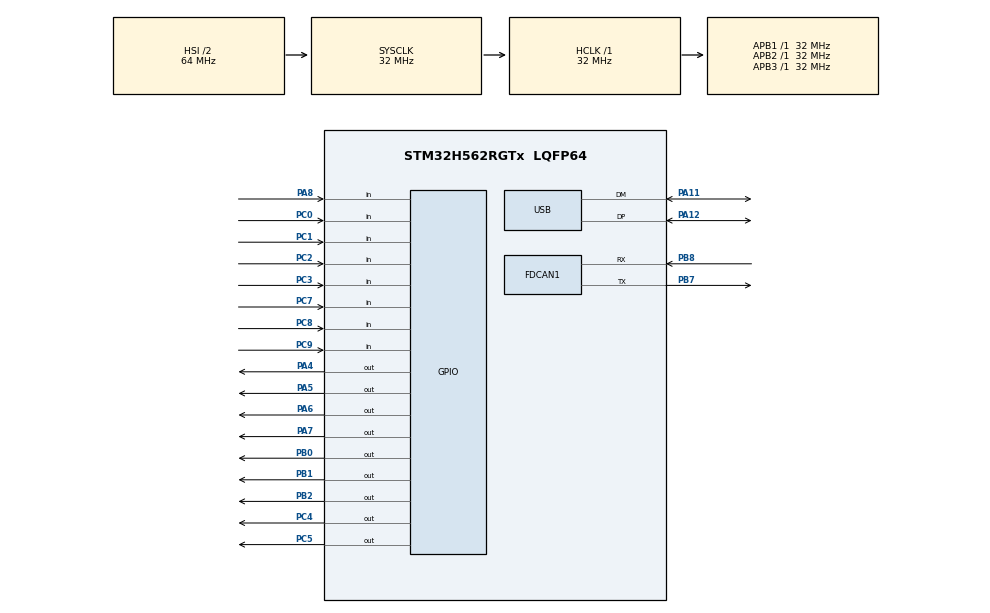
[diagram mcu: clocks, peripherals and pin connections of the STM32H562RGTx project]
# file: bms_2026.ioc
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BOOTPATH.BootPathName=LEGACY
BOOTPATH.UserSelectedBootPath=LEGACY
CORTEX_M33_NS.userName=CORTEX_M33
FDCAN1.CalculateBaudRateNominal=1791666
FDCAN1.CalculateTimeBitNominal=558
FDCAN1.CalculateTimeQuantumNominal=186.04651162790697
Mcu.Family=STM32H5
Mcu.Name=STM32H562RGTx
Mcu.Package=LQFP64
NVIC.PriorityGroup=NVIC_PRIORITYGROUP_4
PA11.Mode=Device
PA11.Signal=USB_DM
PA12.Mode=Device
PA12.Signal=USB_DP
PA4.Signal=GPIO_Output
PA5.Signal=GPIO_Output
PA6.Signal=GPIO_Output
PA7.Signal=GPIO_Output
PA8.Signal=GPIO_Input
PB0.Signal=GPIO_Output
PB1.Signal=GPIO_Output
PB2.Signal=GPIO_Output
PB7.Mode=FDCAN_Activate
PB7.Signal=FDCAN1_TX
PB8.Mode=FDCAN_Activate
PB8.Signal=FDCAN1_RX
PC0.Signal=GPIO_Input
PC1.Signal=GPIO_Input
PC2.Signal=GPIO_Input
PC3.Signal=GPIO_Input
PC4.Signal=GPIO_Output
PC5.Signal=GPIO_Output
PC7.Signal=GPIO_Input
PC8.Signal=GPIO_Input
PC9.Signal=GPIO_Input
ProjectManager.HeapSize=0x200
ProjectManager.StackSize=0x400
ProjectManager.TargetToolchain=STM32CubeIDE
RCC.ADCFreq_Value=32000000
RCC.AHBFreq_Value=32000000
RCC.APB1Freq_Value=32000000
RCC.APB1TimFreq_Value=32000000
RCC.APB2Freq_Value=32000000
RCC.APB2TimFreq_Value=32000000
RCC.APB3Freq_Value=32000000
RCC.CSI_VALUE=4000000
RCC.CortexFreq_Value=32000000
RCC.EPOD_VALUE=4000000
RCC.FDCANClockSelection=RCC_FDCANCLKSOURCE_PLL1Q
RCC.HCLKFreq_Value=32000000
RCC.HSE_VALUE=25000000
RCC.HSI48_VALUE=48000000
RCC.HSI_VALUE=64000000
RCC.LSE_VALUE=32768
RCC.LSIRC_VALUE=32000
RCC.PLL1Q=6
RCC.SYSCLKFreq_VALUE=32000000
RCC.USBFreq_Value=48000000
RCC.VCOOutputFreq_Value=516000000
USB.VirtualMode=Device_Only
VP_BOOTPATH_VS_BOOTPATH.Mode=BP_Activate
VP_CORTEX_M33_NS_VS_Hclk.Mode=Hclk_Mode
VP_MEMORYMAP_VS_MEMORYMAP.Mode=CurAppReg
VP_PWR_VS_LPOM.Mode=PowerOptimisation
VP_PWR_VS_SECSignals.Mode=Security/Privilege
board=custom

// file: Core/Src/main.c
/* USER CODE BEGIN Header */
/**
  ******************************************************************************
  * @file           : main.c
  * @brief          : Main program body
  ******************************************************************************
  * @attention
  *
  * Copyright (c) 2026 STMicroelectronics.
  * All rights reserved.
  *
  * This software is licensed under terms that can be found in the LICENSE file
  * in the root directory of this software component.
  * If no LICENSE file comes with this software, it is provided AS-IS.
  *
  ******************************************************************************
  */
/* USER CODE END Header */
#include "main.h"

/* USER CODE BEGIN PD */
#define NUM_RELAYS 8
#define DEBOUNCE_MS 50
/* USER CODE END PD */

FDCAN_HandleTypeDef hfdcan1;

PCD_HandleTypeDef hpcd_USB_DRD_FS;

// Button-to-relay pin mapping
GPIO_TypeDef* btn_port[NUM_RELAYS] = {GPIOC, GPIOC, GPIOC, GPIOC, GPIOC, GPIOC, GPIOC, GPIOA};
uint16_t btn_pin[NUM_RELAYS] = {GPIO_PIN_0, GPIO_PIN_1, GPIO_PIN_2, GPIO_PIN_3, GPIO_PIN_7, GPIO_PIN_8, GPIO_PIN_9, GPIO_PIN_8};

GPIO_TypeDef* relay_port[NUM_RELAYS] = {GPIOA, GPIOA, GPIOA, GPIOA, GPIOC, GPIOC, GPIOB, GPIOB};
uint16_t relay_pin[NUM_RELAYS] = {GPIO_PIN_4, GPIO_PIN_5, GPIO_PIN_6, GPIO_PIN_7, GPIO_PIN_4, GPIO_PIN_5, GPIO_PIN_0, GPIO_PIN_1};

uint8_t relay_state[NUM_RELAYS] = {0};
uint8_t btn_stable[NUM_RELAYS] = {1, 1, 1, 1, 1, 1, 1, 1};
uint8_t btn_raw[NUM_RELAYS] = {1, 1, 1, 1, 1, 1, 1, 1};
uint32_t btn_debounce_time[NUM_RELAYS] = {0};

void SystemClock_Config(void);
static void MX_GPIO_Init(void);
static void MX_FDCAN1_Init(void);
static void MX_USB_PCD_Init(void);

int main(void)
{

  /* MCU Configuration--------------------------------------------------------*/

  /* Reset of all peripherals, Initializes the Flash interface and the Systick. */
  HAL_Init();

  /* Configure the system clock */
  SystemClock_Config();

  /* Initialize all configured peripherals */
  MX_GPIO_Init();
  MX_FDCAN1_Init();
  MX_USB_PCD_Init();

  /* Infinite loop */
  while (1)
  {
	  /* USER CODE BEGIN 3 */
	  for (int i = 0; i < NUM_RELAYS; i++) {
	      uint8_t reading = HAL_GPIO_ReadPin(btn_port[i], btn_pin[i]);

	      if (reading != btn_raw[i]) {
	          btn_debounce_time[i] = HAL_GetTick();
	          btn_raw[i] = reading;
	      }

	      if ((HAL_GetTick() - btn_debounce_time[i]) > DEBOUNCE_MS) {
	          if (btn_raw[i] != btn_stable[i]) {
	              btn_stable[i] = btn_raw[i];
	              // Toggle on press (falling edge)
	              if (btn_stable[i] == GPIO_PIN_RESET) {
	                  relay_state[i] ^= 1;
	                  HAL_GPIO_WritePin(relay_port[i], relay_pin[i],
	                      relay_state[i] ? GPIO_PIN_SET : GPIO_PIN_RESET);
	              }
	          }
	      }
	  }
	  /* USER CODE END 3 */
  }
}

void SystemClock_Config(void)
{
  RCC_OscInitTypeDef RCC_OscInitStruct = {0};
  RCC_ClkInitTypeDef RCC_ClkInitStruct = {0};

  /** Configure the main internal regulator output voltage
  */
  __HAL_PWR_VOLTAGESCALING_CONFIG(PWR_REGULATOR_VOLTAGE_SCALE3);

  while(!__HAL_PWR_GET_FLAG(PWR_FLAG_VOSRDY)) {}

  /** Initializes the RCC Oscillators according to the specified parameters
  * in the RCC_OscInitTypeDef structure.
  */
  RCC_OscInitStruct.OscillatorType = RCC_OSCILLATORTYPE_HSI48|RCC_OSCILLATORTYPE_HSI
                              |RCC_OSCILLATORTYPE_CSI;
  RCC_OscInitStruct.HSIState = RCC_HSI_ON;
  RCC_OscInitStruct.HSIDiv = RCC_HSI_DIV2;
  RCC_OscInitStruct.HSICalibrationValue = RCC_HSICALIBRATION_DEFAULT;
  RCC_OscInitStruct.HSI48State = RCC_HSI48_ON;
  RCC_OscInitStruct.CSIState = RCC_CSI_ON;
  RCC_OscInitStruct.CSICalibrationValue = RCC_CSICALIBRATION_DEFAULT;
  RCC_OscInitStruct.PLL.PLLState = RCC_PLL_ON;
  RCC_OscInitStruct.PLL.PLLSource = RCC_PLL1_SOURCE_CSI;
  RCC_OscInitStruct.PLL.PLLM = 1;
  RCC_OscInitStruct.PLL.PLLN = 129;
  RCC_OscInitStruct.PLL.PLLP = 2;
  RCC_OscInitStruct.PLL.PLLQ = 6;
  RCC_OscInitStruct.PLL.PLLR = 2;
  RCC_OscInitStruct.PLL.PLLRGE = RCC_PLL1_VCIRANGE_2;
  RCC_OscInitStruct.PLL.PLLVCOSEL = RCC_PLL1_VCORANGE_WIDE;
  RCC_OscInitStruct.PLL.PLLFRACN = 0;
  if (HAL_RCC_OscConfig(&RCC_OscInitStruct) != HAL_OK)
  {
    Error_Handler();
  }

  /** Initializes the CPU, AHB and APB buses clocks
  */
  RCC_ClkInitStruct.ClockType = RCC_CLOCKTYPE_HCLK|RCC_CLOCKTYPE_SYSCLK
                              |RCC_CLOCKTYPE_PCLK1|RCC_CLOCKTYPE_PCLK2
                              |RCC_CLOCKTYPE_PCLK3;
  RCC_ClkInitStruct.SYSCLKSource = RCC_SYSCLKSOURCE_HSI;
  RCC_ClkInitStruct.AHBCLKDivider = RCC_SYSCLK_DIV1;
  RCC_ClkInitStruct.APB1CLKDivider = RCC_HCLK_DIV1;
  RCC_ClkInitStruct.APB2CLKDivider = RCC_HCLK_DIV1;
  RCC_ClkInitStruct.APB3CLKDivider = RCC_HCLK_DIV1;

  if (HAL_RCC_ClockConfig(&RCC_ClkInitStruct, FLASH_LATENCY_1) != HAL_OK)
  {
    Error_Handler();
  }

  /** Configure the programming delay
  */
  __HAL_FLASH_SET_PROGRAM_DELAY(FLASH_PROGRAMMING_DELAY_0);
}

static void MX_FDCAN1_Init(void)
{

  hfdcan1.Instance = FDCAN1;
  hfdcan1.Init.ClockDivider = FDCAN_CLOCK_DIV1;
  hfdcan1.Init.FrameFormat = FDCAN_FRAME_CLASSIC;
  hfdcan1.Init.Mode = FDCAN_MODE_NORMAL;
  hfdcan1.Init.AutoRetransmission = DISABLE;
  hfdcan1.Init.TransmitPause = DISABLE;
  hfdcan1.Init.ProtocolException = DISABLE;
  hfdcan1.Init.NominalPrescaler = 16;
  hfdcan1.Init.NominalSyncJumpWidth = 1;
  hfdcan1.Init.NominalTimeSeg1 = 1;
  hfdcan1.Init.NominalTimeSeg2 = 1;
  hfdcan1.Init.DataPrescaler = 1;
  hfdcan1.Init.DataSyncJumpWidth = 1;
  hfdcan1.Init.DataTimeSeg1 = 1;
  hfdcan1.Init.DataTimeSeg2 = 1;
  hfdcan1.Init.StdFiltersNbr = 0;
  hfdcan1.Init.ExtFiltersNbr = 0;
  hfdcan1.Init.TxFifoQueueMode = FDCAN_TX_FIFO_OPERATION;
  if (HAL_FDCAN_Init(&hfdcan1) != HAL_OK)
  {
    Error_Handler();
  }

}

static void MX_USB_PCD_Init(void)
{

  hpcd_USB_DRD_FS.Instance = USB_DRD_FS;
  hpcd_USB_DRD_FS.Init.dev_endpoints = 8;
  hpcd_USB_DRD_FS.Init.speed = USBD_FS_SPEED;
  hpcd_USB_DRD_FS.Init.phy_itface = PCD_PHY_EMBEDDED;
  hpcd_USB_DRD_FS.Init.Sof_enable = DISABLE;
  hpcd_USB_DRD_FS.Init.low_power_enable = DISABLE;
  hpcd_USB_DRD_FS.Init.lpm_enable = DISABLE;
  hpcd_USB_DRD_FS.Init.battery_charging_enable = DISABLE;
  hpcd_USB_DRD_FS.Init.vbus_sensing_enable = DISABLE;
  hpcd_USB_DRD_FS.Init.bulk_doublebuffer_enable = DISABLE;
  hpcd_USB_DRD_FS.Init.iso_singlebuffer_enable = DISABLE;
  if (HAL_PCD_Init(&hpcd_USB_DRD_FS) != HAL_OK)
  {
    Error_Handler();
  }

}

static void MX_GPIO_Init(void)
{
  GPIO_InitTypeDef GPIO_InitStruct = {0};

  /* GPIO Ports Clock Enable */
  __HAL_RCC_GPIOC_CLK_ENABLE();
  __HAL_RCC_GPIOA_CLK_ENABLE();
  __HAL_RCC_GPIOB_CLK_ENABLE();

  /*Configure GPIO pin Output Level */
  HAL_GPIO_WritePin(GPIOA, GPIO_PIN_4|GPIO_PIN_5|GPIO_PIN_6|GPIO_PIN_7, GPIO_PIN_RESET);

  /*Configure GPIO pin Output Level */
  HAL_GPIO_WritePin(GPIOC, GPIO_PIN_4|GPIO_PIN_5, GPIO_PIN_RESET);

  /*Configure GPIO pin Output Level */
  HAL_GPIO_WritePin(GPIOB, GPIO_PIN_0|GPIO_PIN_1|GPIO_PIN_2, GPIO_PIN_RESET);

  /*Configure GPIO pins : PC0 PC1 PC2 PC3
                           PC7 PC8 PC9 */
  GPIO_InitStruct.Pin = GPIO_PIN_0|GPIO_PIN_1|GPIO_PIN_2|GPIO_PIN_3
                          |GPIO_PIN_7|GPIO_PIN_8|GPIO_PIN_9;
  GPIO_InitStruct.Mode = GPIO_MODE_INPUT;
  GPIO_InitStruct.Pull = GPIO_PULLUP;
  HAL_GPIO_Init(GPIOC, &GPIO_InitStruct);

  /*Configure GPIO pins : PA4 PA5 PA6 PA7 */
  GPIO_InitStruct.Pin = GPIO_PIN_4|GPIO_PIN_5|GPIO_PIN_6|GPIO_PIN_7;
  GPIO_InitStruct.Mode = GPIO_MODE_OUTPUT_PP;
  GPIO_InitStruct.Pull = GPIO_NOPULL;
  GPIO_InitStruct.Speed = GPIO_SPEED_FREQ_LOW;
  HAL_GPIO_Init(GPIOA, &GPIO_InitStruct);

  /*Configure GPIO pins : PC4 PC5 */
  GPIO_InitStruct.Pin = GPIO_PIN_4|GPIO_PIN_5;
  GPIO_InitStruct.Mode = GPIO_MODE_OUTPUT_PP;
  GPIO_InitStruct.Pull = GPIO_NOPULL;
  GPIO_InitStruct.Speed = GPIO_SPEED_FREQ_LOW;
  HAL_GPIO_Init(GPIOC, &GPIO_InitStruct);

  /*Configure GPIO pins : PB0 PB1 PB2 */
  GPIO_InitStruct.Pin = GPIO_PIN_0|GPIO_PIN_1|GPIO_PIN_2;
  GPIO_InitStruct.Mode = GPIO_MODE_OUTPUT_PP;
  GPIO_InitStruct.Pull = GPIO_NOPULL;
  GPIO_InitStruct.Speed = GPIO_SPEED_FREQ_LOW;
  HAL_GPIO_Init(GPIOB, &GPIO_InitStruct);

  /*Configure GPIO pin : PA8 */
  GPIO_InitStruct.Pin = GPIO_PIN_8;
  GPIO_InitStruct.Mode = GPIO_MODE_INPUT;
  GPIO_InitStruct.Pull = GPIO_PULLUP;
  HAL_GPIO_Init(GPIOA, &GPIO_InitStruct);

}

void Error_Handler(void)
{
  __disable_irq();
  while (1)
  {
  }
}
